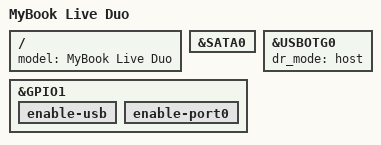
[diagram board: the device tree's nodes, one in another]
/*
 * Device Tree Source for AMCC Canyonlands (460EX)
 *
 * Copyright 2008 DENX Software Engineering, Stefan Roese <sr@denx.de>
 * (c) Copyright 2010 Western Digital Technologies, Inc. All Rights Reserved.
 *
 * This file is licensed under the terms of the GNU General Public
 * License version 2.  This program is licensed "as is" without
 * any warranty of any kind, whether express or implied.
 */

/dts-v1/;

#include "apollo3g.dtsi"

/ {
	model = "MyBook Live Duo";
};

&SATA0 {
	status = "okay";
};

&USBOTG0 {
	status = "okay";
	dr_mode = "host";
};

&GPIO1 {
	enable-usb {
		status = "okay";
	};

	enable-port0 {
		status = "okay";
	};
};
